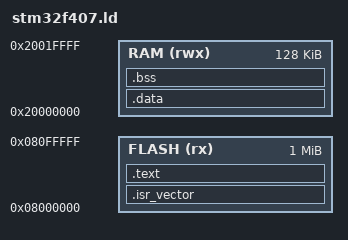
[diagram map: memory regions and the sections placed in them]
/* Minimal linker script for STM32F407 (matches Renode's stm32f4_discovery). */
ENTRY(Reset_Handler)

MEMORY
{
    FLASH (rx)  : ORIGIN = 0x08000000, LENGTH = 1024K
    RAM   (rwx) : ORIGIN = 0x20000000, LENGTH = 128K
}

_estack = ORIGIN(RAM) + LENGTH(RAM);   /* top of stack (full-descending) */

SECTIONS
{
    .isr_vector : { KEEP(*(.isr_vector)) } > FLASH

    .text :
    {
        *(.text*)
        *(.rodata*)
        . = ALIGN(4);
        _etext = .;
    } > FLASH

    /* .data: load address in FLASH, run address in RAM (copied by startup) */
    .data : AT (_etext)
    {
        _sdata = .;
        *(.data*)
        . = ALIGN(4);
        _edata = .;
    } > RAM

    .bss :
    {
        _sbss = .;
        *(.bss*)
        *(COMMON)
        . = ALIGN(4);
        _ebss = .;
    } > RAM
}
